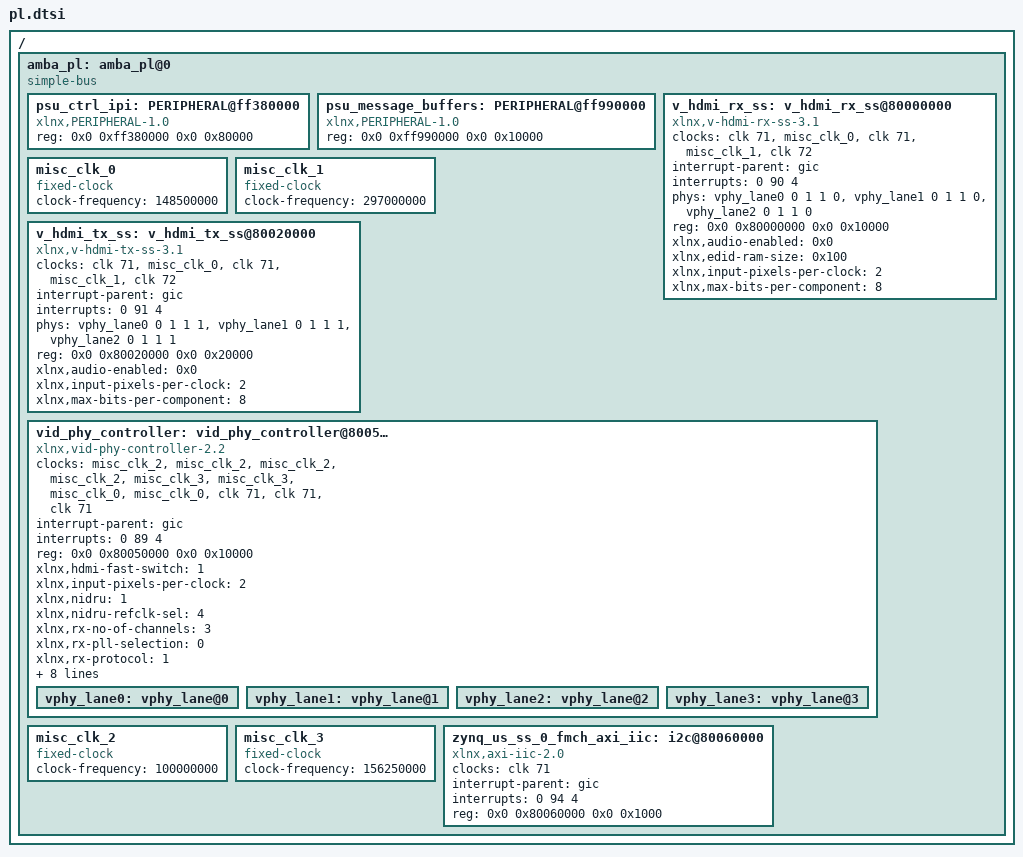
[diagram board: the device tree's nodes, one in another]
/*
 * CAUTION: This file is automatically generated by Xilinx.
 * Version: XSCT 2018.3.1
 * Today is: Thu Aug  8 17:38:56 2019
 */


/ {
	amba_pl: amba_pl@0 {
		#address-cells = <2>;
		#size-cells = <2>;
		compatible = "simple-bus";
		ranges ;
		psu_ctrl_ipi: PERIPHERAL@ff380000 {
			/* This is a place holder node for a custom IP, user may need to update the entries */
			compatible = "xlnx,PERIPHERAL-1.0";
			reg = <0x0 0xff380000 0x0 0x80000>;
		};
		psu_message_buffers: PERIPHERAL@ff990000 {
			/* This is a place holder node for a custom IP, user may need to update the entries */
			compatible = "xlnx,PERIPHERAL-1.0";
			reg = <0x0 0xff990000 0x0 0x10000>;
		};
		v_hdmi_rx_ss: v_hdmi_rx_ss@80000000 {
			/* User needs to change the property xlnx,audio-enabled=<0x1> based on the HDMI audio path */
			clock-names = "s_axi_cpu_aclk", "link_clk", "s_axis_audio_aclk", "video_clk", "s_axis_video_aclk";
			clocks = <&clk 71>, <&misc_clk_0>, <&clk 71>, <&misc_clk_1>, <&clk 72>;
			compatible = "xlnx,v-hdmi-rx-ss-3.1", "xlnx,v-hdmi-rx-ss-3.0";
			interrupt-names = "irq";
			interrupt-parent = <&gic>;
			interrupts = <0 90 4>;
			phy-names = "hdmi-phy0", "hdmi-phy1", "hdmi-phy2";
			phys = <&vphy_lane0 0 1 1 0>, <&vphy_lane1 0 1 1 0>, <&vphy_lane2 0 1 1 0>;
			reg = <0x0 0x80000000 0x0 0x10000>;
			xlnx,audio-enabled = <0x0>;
			xlnx,edid-ram-size = <0x100>;
			xlnx,input-pixels-per-clock = <2>;
			xlnx,max-bits-per-component = <8>;
		};
		misc_clk_0: misc_clk_0 {
			#clock-cells = <0>;
			clock-frequency = <148500000>;
			compatible = "fixed-clock";
		};
		misc_clk_1: misc_clk_1 {
			#clock-cells = <0>;
			clock-frequency = <297000000>;
			compatible = "fixed-clock";
		};
		v_hdmi_tx_ss: v_hdmi_tx_ss@80020000 {
			/* User needs to change the property xlnx,audio-enabled=<0x1> based on the HDMI audio path */
			clock-names = "s_axi_cpu_aclk", "link_clk", "s_axis_audio_aclk", "video_clk", "s_axis_video_aclk";
			clocks = <&clk 71>, <&misc_clk_0>, <&clk 71>, <&misc_clk_1>, <&clk 72>;
			compatible = "xlnx,v-hdmi-tx-ss-3.1", "xlnx,v-hdmi-tx-ss-3.0";
			interrupt-names = "irq";
			interrupt-parent = <&gic>;
			interrupts = <0 91 4>;
			phy-names = "hdmi-phy0", "hdmi-phy1", "hdmi-phy2";
			phys = <&vphy_lane0 0 1 1 1>, <&vphy_lane1 0 1 1 1>, <&vphy_lane2 0 1 1 1>;
			reg = <0x0 0x80020000 0x0 0x20000>;
			xlnx,audio-enabled = <0x0>;
			xlnx,input-pixels-per-clock = <2>;
			xlnx,max-bits-per-component = <8>;
		};
		vid_phy_controller: vid_phy_controller@80050000 {
			clock-names = "mgtrefclk0_pad_p_in", "mgtrefclk0_pad_n_in", "mgtrefclk1_pad_p_in", "mgtrefclk1_pad_n_in", "gtsouthrefclk0_in", "gtsouthrefclk0_odiv2_in", "vid_phy_tx_axi4s_aclk", "vid_phy_rx_axi4s_aclk", "vid_phy_sb_aclk", "vid_phy_axi4lite_aclk", "drpclk";
			clocks = <&misc_clk_2>, <&misc_clk_2>, <&misc_clk_2>, <&misc_clk_2>, <&misc_clk_3>, <&misc_clk_3>, <&misc_clk_0>, <&misc_clk_0>, <&clk 71>, <&clk 71>, <&clk 71>;
			compatible = "xlnx,vid-phy-controller-2.2", "xlnx,vid-phy-controller-2.1";
			interrupt-names = "irq";
			interrupt-parent = <&gic>;
			interrupts = <0 89 4>;
			reg = <0x0 0x80050000 0x0 0x10000>;
			xlnx,hdmi-fast-switch = <1>;
			xlnx,input-pixels-per-clock = <2>;
			xlnx,nidru = <1>;
			xlnx,nidru-refclk-sel = <4>;
			xlnx,rx-no-of-channels = <3>;
			xlnx,rx-pll-selection = <0>;
			xlnx,rx-protocol = <1>;
			xlnx,rx-refclk-sel = <1>;
			xlnx,transceiver-type = <5>;
			xlnx,transceiver-width = <2>;
			xlnx,tx-buffer-bypass = <1>;
			xlnx,tx-no-of-channels = <3>;
			xlnx,tx-pll-selection = <6>;
			xlnx,tx-protocol = <1>;
			xlnx,tx-refclk-sel = <0>;
			vphy_lane0: vphy_lane@0 {
				#phy-cells = <4>;
			};
			vphy_lane1: vphy_lane@1 {
				#phy-cells = <4>;
			};
			vphy_lane2: vphy_lane@2 {
				#phy-cells = <4>;
			};
			vphy_lane3: vphy_lane@3 {
				#phy-cells = <4>;
			};
		};
		misc_clk_2: misc_clk_2 {
			#clock-cells = <0>;
			clock-frequency = <100000000>;
			compatible = "fixed-clock";
		};
		misc_clk_3: misc_clk_3 {
			#clock-cells = <0>;
			clock-frequency = <156250000>;
			compatible = "fixed-clock";
		};
		zynq_us_ss_0_fmch_axi_iic: i2c@80060000 {
			#address-cells = <1>;
			#size-cells = <0>;
			clock-names = "s_axi_aclk";
			clocks = <&clk 71>;
			compatible = "xlnx,axi-iic-2.0", "xlnx,xps-iic-2.00.a";
			interrupt-names = "iic2intc_irpt";
			interrupt-parent = <&gic>;
			interrupts = <0 94 4>;
			reg = <0x0 0x80060000 0x0 0x1000>;
		};
	};
};
